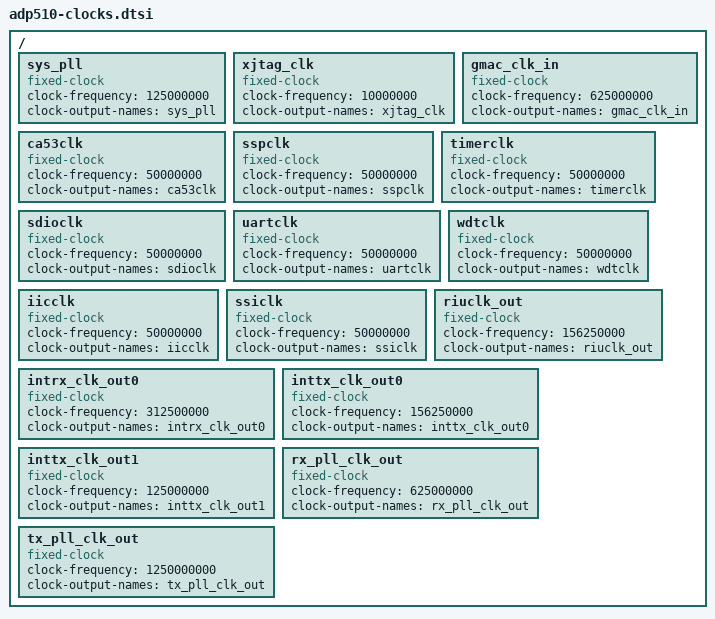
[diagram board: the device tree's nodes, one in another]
/*
 * ARM Juno Platform clocks
 *
 * Copyright (c) 2013-2014 ARM Ltd
 *
 * This file is licensed under a dual GPLv2 or BSD license.
 *
 */
/ {
	/* SoC fixed clocks */
	sys_pll: sys_pll {
		compatible = "fixed-clock";
		#clock-cells = <0>;
		clock-frequency = <125000000>;
		clock-output-names = "sys_pll";
	};

	xjtag_clk: xjtag_clk {
		compatible = "fixed-clock";
		#clock-cells = <0>;
		clock-frequency = <10000000>;
		clock-output-names = "xjtag_clk";
	};

	gmac_clk_in: gmac_clk_in {
		compatible = "fixed-clock";
		#clock-cells = <0>;
		clock-frequency = <625000000>;
		clock-output-names = "gmac_clk_in";
	};


	ca53clk: ca53clk {
		compatible = "fixed-clock";
		#clock-cells = <0>;
		clock-frequency = <50000000>;
		clock-output-names = "ca53clk";
	};
	
	sspclk: sspclk {
		compatible = "fixed-clock";
		#clock-cells = <0>;
		clock-frequency = <50000000>;
		clock-output-names = "sspclk";
	};

	timerclk: timerclk {
		compatible = "fixed-clock";
		#clock-cells = <0>;
		clock-frequency = <50000000>;
		clock-output-names = "timerclk";
	};

	sdioclk: sdioclk {
		compatible = "fixed-clock";
		#clock-cells = <0>;
		clock-frequency = <50000000>;
		clock-output-names = "sdioclk";
	};

	
	uartclk: uartclk {
		compatible = "fixed-clock";
		#clock-cells = <0>;
		clock-frequency = <50000000>;
		clock-output-names = "uartclk";
	};
	
	wdtclk: wdtclk {
		compatible = "fixed-clock";
		#clock-cells = <0>;
		clock-frequency = <50000000>;
		clock-output-names = "wdtclk";
	};

	iicclk: iicclk {
		compatible = "fixed-clock";
		#clock-cells = <0>;
		clock-frequency = <50000000>;
		clock-output-names = "iicclk";
	};

	ssiclk: ssiclk {
		compatible = "fixed-clock";
		#clock-cells = <0>;
		clock-frequency = <50000000>;
		clock-output-names = "ssiclk";
	};

	riuclk_out: riuclk_out {
		compatible = "fixed-clock";
		#clock-cells = <0>;
		clock-frequency = <156250000>;
		clock-output-names = "riuclk_out";
	};

	intrx_clk_out0: intrx_clk_out0 {
		compatible = "fixed-clock";
		#clock-cells = <0>;
		clock-frequency = <312500000>;
		clock-output-names = "intrx_clk_out0";
	};

	inttx_clk_out0: inttx_clk_out0 {
		compatible = "fixed-clock";
		#clock-cells = <0>;
		clock-frequency = <156250000>;
		clock-output-names = "inttx_clk_out0";
	};

	inttx_clk_out1: inttx_clk_out1 {
		compatible = "fixed-clock";
		#clock-cells = <0>;
		clock-frequency = <125000000>;
		clock-output-names = "inttx_clk_out1";
	};

	rx_pll_clk_out: rx_pll_clk_out {
		compatible = "fixed-clock";
		#clock-cells = <0>;
		clock-frequency = <625000000>;
		clock-output-names = "rx_pll_clk_out";
	};

	tx_pll_clk_out: tx_pll_clk_out {
		compatible = "fixed-clock";
		#clock-cells = <0>;
		clock-frequency = <1250000000>;
		clock-output-names = "tx_pll_clk_out";
	};
};
